# NPCX498S register map
File version: 1.0
Registers are 8-bit, read-write, reset 0x0 unless marked. A register's access mark holds for its fields unless they carry their own. Offsets are from the block's base; [hi:lo] are bit positions; {n}, {i} and the like mark numbered series; 'fields as' and 'values as' point back to an identical list.

## LCT
Base 0x400D7000
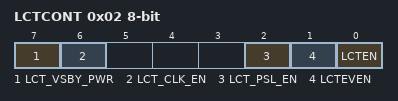
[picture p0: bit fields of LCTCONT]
0x02 LCTCONT — LCT Control Register (LCTCONT)
  [7] LCT_VSBY_PWR — LCT, VSBY Power Select
  [6] LCT_CLK_EN — LCT Clock Enable
  [2] LCT_PSL_EN — LCT PSL Event Enable
  [1] LCTEVEN — LCT Event Enable
  [0] LCTEN — LCT Enable
0x04 LCTSTAT — LCT Status Register (LCTSTAT)
  [0] LCTEVST — LCT Event Status
0x05 LCTSECOND — LCT Seconds Register (LCTSECOND)
0x06 LCTMINUT — LCT Minutes Register (LCTMINUT)
0x08 LCTHOUR — LCT Hours Register (LCTHOUR)
  [4:0] HOURS — Hours Value
0x0A LCTDAY — LCT Days Register (LCTDAY)
  [4:0] DAYS — Days Value
0x0C LCTWEEK — LCT Weeks LSB Register (LCTWEEK)
0x0D LCTWEEKM — LCT Weeks MSB Register (LCTWEEKM)
  [2:0] WEEKS — Weeks Value

## LFCG
Base 0x400B5100
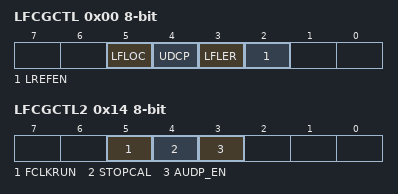
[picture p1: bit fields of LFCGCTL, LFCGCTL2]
0x00 LFCGCTL — LFCG Control Register (LFCGCTL)
  [5] LFLOC — LFCG Register Write Lock
  [4] UDCP — Update Calibration Parameters
  [3] LFLER — LFCG Locked on External Reference
  [2] LREFEN — LPC Clock Reference Enable
0x02 HFRDI 16-bit (reset mask 0xFF) — High-Frequency Reference Divisor I Register (HFRDI)
  [11:0] HFRDI — High-Frequency Reference Divisor I
0x04 HFRDF 16-bit (reset mask 0xFF) — High-Frequency Reference Divisor F Register (HFRDF)
0x06 FRCDIV 16-bit (reset mask 0xFF) — FRCLK Clock Divisor Register (FRCDIV)
  [8:0] FRCDIV — FRCLK Clock Divisor
0x08 DIVCOR1 16-bit (reset mask 0xFF) — Divisor Correction Value 1 Register (DIVCOR1)
  [8:0] DIVCOR1 — Divisor Correction Value 1
0x0A DIVCOR2 16-bit (reset mask 0xFF) — Divisor Correction Value 2 Register (DIVCOR2)
  [8:0] DIVCOR2 — Divisor Correction Value 2
0x14 LFCGCTL2 — LFCG Control 2 Register (LFCGCTL2)
  [5] FCLKRUN — Force PCI_CLK Running
  [4] STOPCAL — Stop Calibration to External Reference
  [3] AUDP_EN — Automatic Update Enable

## MDC
Base 0x4000C000
0x0A HEAD_BASEL 16-bit (reset mask 0xFF) — Header Base Low Register (HEAD_BASEL)
0x0C HEAD_BASEH 16-bit (reset mask 0xFF) — Header Base High Register (HEAD_BASEH)
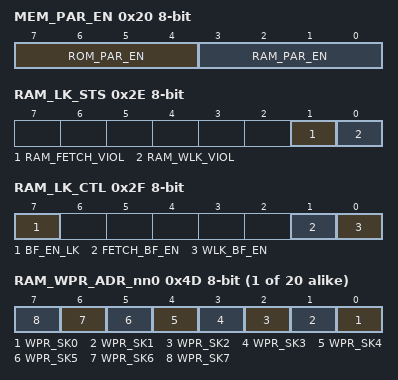
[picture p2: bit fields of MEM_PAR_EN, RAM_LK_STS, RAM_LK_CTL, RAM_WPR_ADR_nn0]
0x20 MEM_PAR_EN — Memory Parity Check Enable Register (MEM_PAR_EN)
  [7:4] ROM_PAR_EN — ROM Parity Check Enable
  [3:0] RAM_PAR_EN — RAM Parity Check Enable
0x22 FWSC — Firmware Scratch Register (FWSC)
0x2E RAM_LK_STS — RAM Lock Status Register (RAM_LK_STS)
  [1] RAM_FETCH_VIOL — RAM Fetch Violation
  [0] RAM_WLK_VIOL — RAM Write Lock Violation
0x2F RAM_LK_CTL — RAM Lock Control Register (RAM_LK_CTL)
  [7] BF_EN_LK — BusFault Trap Enable Lock
  [1] FETCH_BF_EN — RAM Fetch BusFault Trap Enable
  [0] WLK_BF_EN — RAM Write Lock BusFault Trap Enable
{0x4D+i} RAM_WPR_ADR_nn{i} (i=0..19) — RAM Write Protect Block Base Address nn Register (RAM_WPR_ADR_nn)
  [n] WPR_SK{n} (n=0..7) — Write Protect Sector {n}
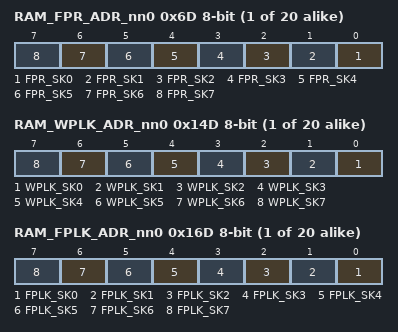
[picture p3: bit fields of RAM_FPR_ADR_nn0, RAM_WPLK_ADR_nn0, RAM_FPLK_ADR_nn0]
{0x6D+i} RAM_FPR_ADR_nn{i} (i=0..19) — RAM Fetch Protect Block Base Address nn Register (RAM_FPR_ADR_nn)
  [n] FPR_SK{n} (n=0..7) — Fetch Protect Sector {n}
{0x14D+i} RAM_WPLK_ADR_nn{i} (i=0..19) — RAM Write Protect Lock Block Base Address nn Register (RAM_WPLK_ADR_nn)
  [n] WPLK_SK{n} (n=0..7) — Write Protect Lock Sector {n}
{0x16D+i} RAM_FPLK_ADR_nn{i} (i=0..19) — RAM Fetch Protect Lock Block Base Address nn Register (RAM_FPLK_ADR_nn)
  [n] FPLK_SK{n} (n=0..7) — Fetch Protect Lock Sector {n}

## MDMA1
Base 0x40011100
Same registers: MDMA2 0x40011200, MDMA3 0x40011300, MDMA4 0x40011400, MDMA5 0x40011500, MDMA6 0x40011600, MDMA7 0x40011700
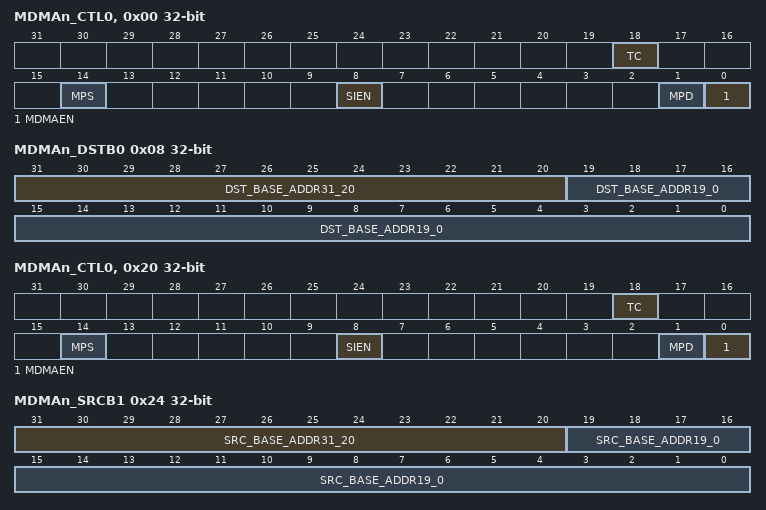
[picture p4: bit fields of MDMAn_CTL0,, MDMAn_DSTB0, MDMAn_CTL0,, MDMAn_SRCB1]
0x00 MDMAn_CTL0, MDMAn_CTL10 32-bit (reset mask 0xFF) — Channel 0/1 Control Register (MDMAn_CTL0, MDMAn_CTL1)
  [18] TC — Terminal Count
  [14] MPS — MDMA Power Save
  [8] SIEN — Stop Interrupt Enable
  [1] MPD — MDMA Power-Down
  [0] MDMAEN — MDMA Enable
0x04 MDMAn_SRCB0 32-bit (reset mask 0xFF) — Channel 0 Source Base Address Register (MDMAn_SRCB0)
0x08 MDMAn_DSTB0 32-bit (reset mask 0xFF) — Channel 0 Destination Base Address Register (MDMAn_DSTB0)
  [31:20] DST_BASE_ADDR31_20 — 32-bit Destination Base Address
  [19:0] DST_BASE_ADDR19_0 — 20-bit Destination Base Address
0x0C MDMAn_TCNT0, MDMAn_TCNT10 32-bit (reset mask 0xFF) — Channel 0/1 Transfer Count Register (MDMAn_TCNT0, MDMAn_TCNT1)
  [12:0] TFR_CNT — 13-bit Transfer Count
0x14 MDMAn_CDST0 32-bit (reset mask 0xFF) — Channel 0 Current Destination Register (MDMAn_CDST0)
0x18 MDMAn_CTCNT0, MDMAn_CTCNT10 32-bit (reset mask 0xFF) — Channel 0/1 Current Transfer Count Register (MDMAn_CTCNT0, MDMAn_CTCNT1)
  [12:0] CURENT_TFR_CNT — 13-bit Current Transfer Count
0x20 MDMAn_CTL0, MDMAn_CTL11 32-bit (reset mask 0xFF) — Channel 0/1 Control Register (MDMAn_CTL0, MDMAn_CTL1)
  fields as MDMAn_CTL0,
0x24 MDMAn_SRCB1 32-bit (reset mask 0xFF) — Channel 1 Source Base Address Register (MDMAn_SRCB1)
  [31:20] SRC_BASE_ADDR31_20 — 12-bit Source Base Address
  [19:0] SRC_BASE_ADDR19_0 — 20-bit Source Base Address
0x28 MDMAn_DSTB1 32-bit (reset mask 0xFF) — Channel 1 Destination Base Address Register (MDMAn_DSTB1)
0x2C MDMAn_TCNT0, MDMAn_TCNT11 32-bit (reset mask 0xFF) — Channel 0/1 Transfer Count Register (MDMAn_TCNT0, MDMAn_TCNT1)
  [12:0] TFR_CNT — 13-bit Transfer Count
0x30 MDMAn_CSRC1 32-bit (reset mask 0xFF) — Channel 1 Current Source Register (MDMAn_CSRC1)
0x38 MDMAn_CTCNT0, MDMAn_CTCNT11 32-bit (reset mask 0xFF) — Channel 0/1 Current Transfer Count Register (MDMAn_CTCNT0, MDMAn_CTCNT1)
  [12:0] CURENT_TFR_CNT — 13-bit Current Transfer Count
